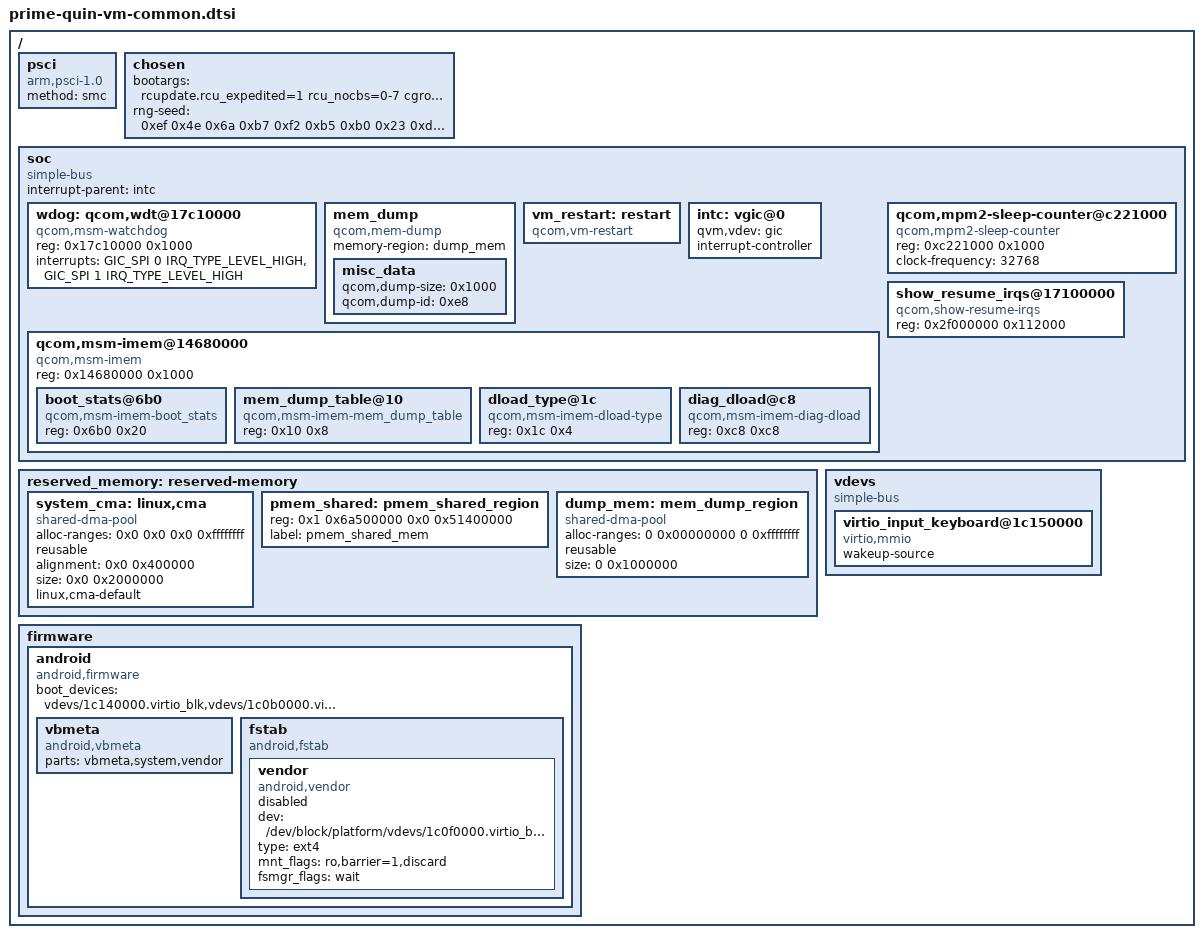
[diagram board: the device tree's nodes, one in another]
// SPDX-License-Identifier: BSD-3-Clause
/*
 * Copyright (c) Qualcomm Technologies, Inc. and/or its subsidiaries.
 */

#include <dt-bindings/interrupt-controller/arm-gic.h>
#include <dt-bindings/arm/msm/qcom_dma_heap_dt_constants.h>

/ {
	#address-cells = <2>;
	#size-cells = <2>;

	psci {
		compatible = "arm,psci-1.0";
		method = "smc";
	};

	chosen {
		bootargs = "rcupdate.rcu_expedited=1 rcu_nocbs=0-7 cgroup.memory=nokmem,nosocket kpti=0 qcom_dma_heaps.enable_bitstream_contig_heap=y arm64.nopauth kasan=off";
		rng-seed = <0xef 0x4e 0x6a 0xb7 0xf2 0xb5 0xb0 0x23 0xdf 0xa7 0xeb 0x2b 0x44 0x40 0x11 0x7d 0x5c 0xbb 0xf1 0x21 0x5d 0x82 0x1a 0x4a 0x04 0xf5 0x93 0x8a 0x7f 0x2a 0xee 0x56>;
	};

	soc: soc { };

	reserved_memory: reserved-memory {
		#address-cells = <2>;
		#size-cells = <2>;
		ranges;

		system_cma: linux,cma {
			compatible = "shared-dma-pool";
			alloc-ranges = <0x0 0x0 0x0 0xffffffff>;
			reusable;
			alignment = <0x0 0x400000>;
			size = <0x0 0x2000000>;
			linux,cma-default;
		};

		pmem_shared: pmem_shared_region {
			reg = <0x1 0x6a500000 0x0 0x51400000>;
			label = "pmem_shared_mem";
		};

		dump_mem: mem_dump_region {
			compatible = "shared-dma-pool";
			alloc-ranges = <0 0x00000000 0 0xffffffff>;
			reusable;
			size = <0 0x1000000>;
		};
	};

	vdevs {
		compatible = "simple-bus";
		virtio_input_keyboard@1c150000 {
			compatible = "virtio,mmio";
			wakeup-source;
		};
	};

	firmware: firmware {
		android {
			compatible = "android,firmware";
			boot_devices = "vdevs/1c140000.virtio_blk,vdevs/1c0b0000.virtio_blk,vdevs/1c0f0000.virtio_blk,vdevs/1c410000.virtio_blk,vdevs/1c130000.virtio_blk,vdevs/1c0e0000.virtio_blk,vdevs/1c100000.virtio_blk,vdevs/1c170000.virtio_blk,vdevs/1c180000.virtio_blk,vdevs/1c110000.virtio_blk,vdevs/1c120000.virtio_blk,vdevs/1c210000.virtio_blk,vdevs/1c220000.virtio_blk,vdevs/1c230000.virtio_blk,vdevs/1c240000.virtio_blk,vdevs/1c250000.virtio_blk,vdevs/1c260000.virtio_blk,vdevs/1c280000.virtio_blk,vdevs/1c290000.virtio_blk,vdevs/1c310000.virtio_blk,vdevs/1c320000.virtio_blk";

			vbmeta {
				compatible = "android,vbmeta";
				parts = "vbmeta,system,vendor";
			};

			fstab {
				compatible = "android,fstab";
				vendor {
					compatible = "android,vendor";
					dev="/dev/block/platform/vdevs/1c0f0000.virtio_blk/vdc";
					type = "ext4";
					mnt_flags = "ro,barrier=1,discard";
					fsmgr_flags = "wait";
					status = "disabled";
				};
			};
		};
	};
};

&soc {
	#address-cells = <1>;
	#size-cells = <1>;
	interrupt-parent = <&intc>;
	ranges = <0x0 0x0 0x0 0xffffffff>;
	compatible = "simple-bus";

	wdog: qcom,wdt@17c10000 {
		compatible = "qcom,msm-watchdog";
		reg = <0x17c10000 0x1000>;
		reg-names = "wdt-base";
		interrupts = <GIC_SPI 0 IRQ_TYPE_LEVEL_HIGH>,
			     <GIC_SPI 1 IRQ_TYPE_LEVEL_HIGH>;
	};

	mem_dump {
		compatible = "qcom,mem-dump";
		memory-region = <&dump_mem>;

		misc_data {
			qcom,dump-size = <0x1000>;
			qcom,dump-id = <0xe8>;
		};
	};

	vm_restart: restart {
		compatible = "qcom,vm-restart";
		status = "ok";
	};

	intc: vgic@0 {
		qvm,vdev = "gic";
		#interrupt-cells = <3>;
		interrupt-controller;
	};

	qcom,msm-imem@14680000 {
		compatible = "qcom,msm-imem";
		reg = <0x14680000 0x1000>;
		ranges = <0x0 0x14680000 0x1000>;
		#address-cells = <1>;
		#size-cells = <1>;

		boot_stats@6b0 {
			compatible = "qcom,msm-imem-boot_stats";
			reg = <0x6b0 0x20>;
		};

		mem_dump_table@10 {
			compatible = "qcom,msm-imem-mem_dump_table";
			reg = <0x10 0x8>;
		};

		dload_type@1c {
			compatible = "qcom,msm-imem-dload-type";
			reg = <0x1c 0x4>;
		};

		diag_dload@c8 {
			compatible = "qcom,msm-imem-diag-dload";
			reg = <0xc8 0xc8>;
		};
	};

	qcom,mpm2-sleep-counter@c221000 {
		compatible = "qcom,mpm2-sleep-counter";
		reg = <0xc221000 0x1000>;
		clock-frequency = <32768>;
	};

	show_resume_irqs@17100000 {
		compatible = "qcom,show-resume-irqs";
		reg = <0x2f000000 0x112000>;
	};
};
